AUTOSAR XML (schema 4-2-2)
standard types defined: uint8, uint16, boolean, void
package /WiperCtrl_Pkg/Units
  unit MilliAmpere: display-name=mA
  unit KiloMeterPerHour: display-name=km/h
  unit Percent: display-name=%
package /WiperCtrl_Pkg/DataTypes
  16 x impl type:
    WiperPos_T: category=VALUE, base-type=uint8, compu {0=WIPERPOS_OFF, 1=WIPERPOS_INT, 2=WIPERPOS_LOW, 3=WIPERPOS_HIGH}
    IntLevel_T: category=VALUE, base-type=uint8, range raw 1..4
    RainIntensity_T: category=VALUE, base-type=uint8, compu {identical; unit %}, range phys 0..100
    RainSensorStatus_T: category=VALUE, base-type=uint8, compu {0=RAINSENSOR_OK, 1=RAINSENSOR_INIT, 2=RAINSENSOR_FAULT}
    PowerMode_T: category=VALUE, base-type=uint8, compu {0=POWERMODE_OFF, 1=POWERMODE_ACC, 2=POWERMODE_RUN, 3=POWERMODE_CRANK}
    MotorCurrent_T: category=VALUE, base-type=uint16, compu {phys=raw; unit mA} "Motor current from IoHwAb, 1 mA per bit."
    VehSpeed_T: category=VALUE, base-type=uint16, compu {phys=raw*0.1; unit km/h}
    MotorSpeedCmd_T: category=VALUE, base-type=uint8, compu {0=MOTORSPEED_STOP, 1=MOTORSPEED_LOW, 2=MOTORSPEED_HIGH}
    WiperStatus_T: category=VALUE, base-type=uint8, compu {0=WIPERSTATUS_OFF, 1=WIPERSTATUS_INTERVAL, 2=WIPERSTATUS_AUTO, 3=WIPERSTATUS_LOW, 4=WIPERSTATUS_HIGH, 5=WIPERSTATUS_WASH, 6=WIPERSTATUS_FAULT}
    boolean_T: category=VALUE, base-type=boolean
    uint8_T: category=VALUE, base-type=uint8
    uint16_T: category=VALUE, base-type=uint16
    Dem_EventStatusType: category=VALUE, base-type=uint8
    NvM_RequestResultType: category=VALUE, base-type=uint8
    NvM_SrcPtrType: category=DATA_REFERENCE, sw-pointer-target-props={target-category=VALUE, base-type=void, sw-impl-policy=CONST}
    WiperCtrl_NvBlockType: category=STRUCTURE
      element WashCycleCnt: implementation-data-type=uint16_T
      element BlockEventCnt: implementation-data-type=uint8_T
      element Reserved: implementation-data-type=uint8_T
package /WiperCtrl_Pkg/PortInterfaces
  7 x sender receiver interface:
    StalkSwitch_I
      data WiperPos: type=WiperPos_T
      data IntLevel: type=IntLevel_T
      data WashReq: type=boolean_T
    RainSensor_I
      data Intensity: type=RainIntensity_T
      data Status: type=RainSensorStatus_T
    PowerMode_I
      data Mode: type=PowerMode_T
    WiperMotorFb_I
      data ParkPos: type=boolean_T
      data Current: type=MotorCurrent_T
    VehicleSpeed_I
      data Speed: type=VehSpeed_T
    WiperMotorCmd_I
      data Speed: type=MotorSpeedCmd_T
    WiperStatus_I
      data Mode: type=WiperStatus_T
  client server interface WasherPump_I
    operation SetState
      arg On: type=boolean_T, direction=IN
  client server interface DiagnosticMonitor: is-service=true
    operation SetEventStatus: possible-error=DiagnosticMonitor/E_NOT_OK
      arg EventStatus: type=Dem_EventStatusType, direction=IN
    error E_NOT_OK: error-code=1
  client server interface NvMService: is-service=true
    operation GetErrorStatus: possible-error=NvMService/E_NOT_OK
      arg ErrorStatus: type=NvM_RequestResultType, direction=OUT
    operation WriteBlock: possible-error=NvMService/E_NOT_OK
      arg SrcPtr: type=NvM_SrcPtrType, direction=IN
    error E_NOT_OK: error-code=1
package /WiperCtrl_Pkg/SwComponentTypes
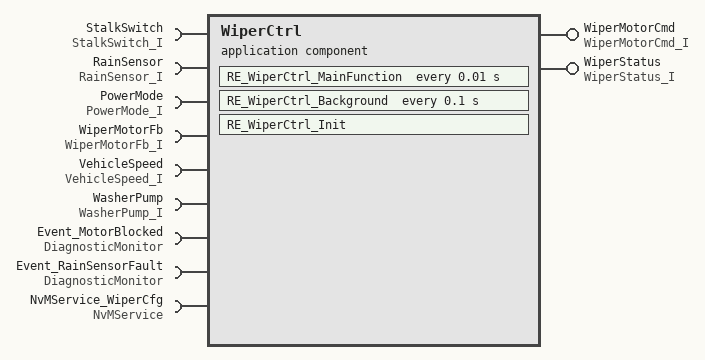
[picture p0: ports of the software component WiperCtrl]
  application sw component type WiperCtrl  # Front wiper control: interval, low, high, rain sensor AUTO, wash/wipe, motor blocking protection.
    5 x require port:
      StalkSwitch: required-interface=StalkSwitch_I
      RainSensor: required-interface=RainSensor_I
      PowerMode: required-interface=PowerMode_I
      WiperMotorFb: required-interface=WiperMotorFb_I
      VehicleSpeed: required-interface=VehicleSpeed_I
    provide port WiperMotorCmd: provided-interface=WiperMotorCmd_I
    provide port WiperStatus: provided-interface=WiperStatus_I
    4 x require port:
      WasherPump: required-interface=WasherPump_I
      Event_MotorBlocked: required-interface=DiagnosticMonitor
      Event_RainSensorFault: required-interface=DiagnosticMonitor
      NvMService_WiperCfg: required-interface=NvMService
    behavior WiperCtrl_IB: handle-termination-and-restart=NO-SUPPORT
      ar-typed-per-instance-memorys:
        data NvMirror: type=WiperCtrl_NvBlockType
      init event EV_Init: start-on-event=RE_WiperCtrl_Init
      timing event EV_Main_10ms: start-on-event=RE_WiperCtrl_MainFunction, period=0.01
      timing event EV_Background_100ms: start-on-event=RE_WiperCtrl_Background, period=0.1
      runnable RE_WiperCtrl_Init
      runnable RE_WiperCtrl_MainFunction
        data-read-access:
          access DRA_VehicleSpeed_Speed: accessed-variable=VehicleSpeed.Speed
        data-receive-point-by-arguments:
          8 x access:
            DRP_StalkSwitch_WiperPos: accessed-variable=StalkSwitch.WiperPos
            DRP_StalkSwitch_IntLevel: accessed-variable=StalkSwitch.IntLevel
            DRP_StalkSwitch_WashReq: accessed-variable=StalkSwitch.WashReq
            DRP_RainSensor_Intensity: accessed-variable=RainSensor.Intensity
            DRP_RainSensor_Status: accessed-variable=RainSensor.Status
            DRP_PowerMode_Mode: accessed-variable=PowerMode.Mode
            DRP_WiperMotorFb_ParkPos: accessed-variable=WiperMotorFb.ParkPos
            DRP_WiperMotorFb_Current: accessed-variable=WiperMotorFb.Current
        data-send-points:
          access DSP_WiperMotorCmd_Speed: accessed-variable=WiperMotorCmd.Speed
          access DSP_WiperStatus_Mode: accessed-variable=WiperStatus.Mode
        parameter access PA_RainThreshold: accessed-parameter=RainThreshold
        sync call SCP_WasherPump_SetState: operation=WasherPump.SetState, timeout=0
      runnable RE_WiperCtrl_Background
        4 x sync call, all with timeout=0:
          SCP_Event_MotorBlocked_SetEventStatus: operation=Event_MotorBlocked.SetEventStatus
          SCP_Event_RainSensorFault_SetEventStatus: operation=Event_RainSensorFault.SetEventStatus
          SCP_NvMService_WiperCfg_GetErrorStatus: operation=NvMService_WiperCfg.GetErrorStatus
          SCP_NvMService_WiperCfg_WriteBlock: operation=NvMService_WiperCfg.WriteBlock
      shared-parameters:
        parameter data prototype RainThreshold: type=RainIntensity_T, init-value=10  # AUTO mode: minimum effective rain intensity that triggers wiping [%].
